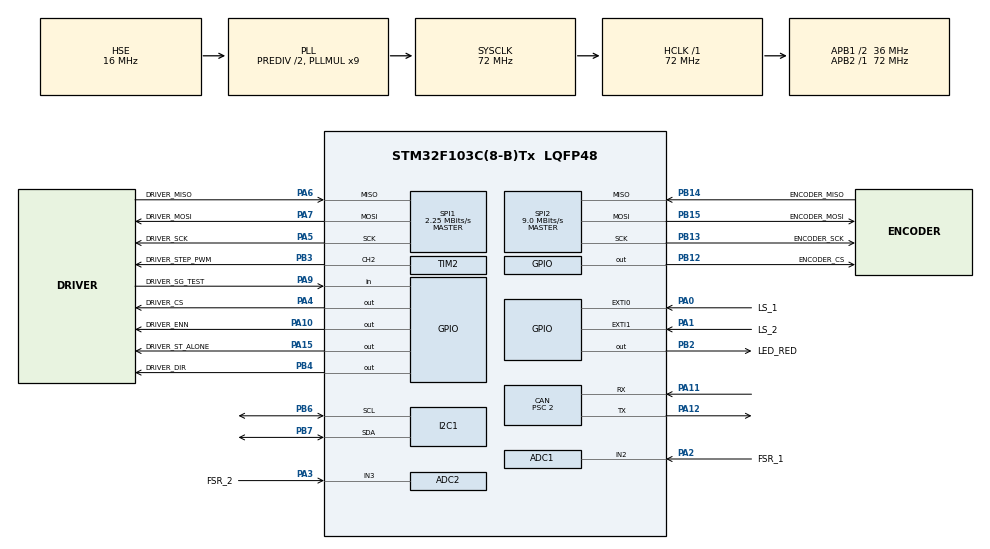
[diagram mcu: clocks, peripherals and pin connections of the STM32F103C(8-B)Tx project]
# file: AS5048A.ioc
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ADC1.Channel-0\#ChannelRegularConversion=ADC_CHANNEL_2
ADC1.EnableAnalogWatchDog=true
ADC1.NbrOfConversionFlag=1
ADC1.Rank-0\#ChannelRegularConversion=1
ADC1.SamplingTime-0\#ChannelRegularConversion=ADC_SAMPLETIME_1CYCLE_5
ADC1.WatchdogChannel=ADC_CHANNEL_2
ADC1.master=1
ADC2.Channel-0\#ChannelRegularConversion=ADC_CHANNEL_3
ADC2.EnableAnalogWatchDog=true
ADC2.NbrOfConversionFlag=1
ADC2.Rank-0\#ChannelRegularConversion=1
ADC2.SamplingTime-0\#ChannelRegularConversion=ADC_SAMPLETIME_1CYCLE_5
ADC2.WatchdogChannel=ADC_CHANNEL_3
CAN.BS1=CAN_BS1_15TQ
CAN.BS2=CAN_BS2_2TQ
CAN.CalculateBaudRate=1000000
CAN.CalculateTimeBit=1000
CAN.CalculateTimeQuantum=55.55555555555556
CAN.NART=ENABLE
CAN.Prescaler=2
CAN.SJW=CAN_SJW_2TQ
Mcu.Family=STM32F1
Mcu.Name=STM32F103C(8-B)Tx
Mcu.Package=LQFP48
NVIC.ADC1_2_IRQn=true\:0\:0\:false\:false\:true\:true\:true\:true
NVIC.EXTI0_IRQn=true\:1\:0\:true\:false\:true\:true\:true\:true
NVIC.EXTI1_IRQn=true\:1\:0\:true\:false\:true\:true\:true\:true
NVIC.PriorityGroup=NVIC_PRIORITYGROUP_4
NVIC.USB_LP_CAN1_RX0_IRQn=true\:2\:0\:true\:false\:true\:true\:true\:true
PA0-WKUP.GPIO_Label=LS_1
PA0-WKUP.GPIO_ModeDefaultEXTI=GPIO_MODE_IT_RISING_FALLING
PA0-WKUP.Signal=GPXTI0
PA1.GPIO_Label=LS_2
PA1.GPIO_ModeDefaultEXTI=GPIO_MODE_IT_RISING_FALLING
PA1.Signal=GPXTI1
PA10.GPIO_Label=DRIVER_ENN
PA10.Signal=GPIO_Output
PA11.Mode=CAN_Activate
PA11.Signal=CAN_RX
PA12.Mode=CAN_Activate
PA12.Signal=CAN_TX
PA13.Mode=Serial_Wire
PA13.Signal=SYS_JTMS-SWDIO
PA14.Mode=Serial_Wire
PA14.Signal=SYS_JTCK-SWCLK
PA15.GPIO_Label=DRIVER_ST_ALONE
PA15.Signal=GPIO_Output
PA2.GPIO_Label=FSR_1
PA2.Signal=ADCx_IN2
PA3.GPIO_Label=FSR_2
PA3.Signal=ADCx_IN3
PA4.GPIO_Label=DRIVER_CS
PA4.Signal=GPIO_Output
PA5.GPIO_Label=DRIVER_SCK
PA5.Mode=Full_Duplex_Master
PA5.Signal=SPI1_SCK
PA6.GPIO_Label=DRIVER_MISO
PA6.Mode=Full_Duplex_Master
PA6.Signal=SPI1_MISO
PA7.GPIO_Label=DRIVER_MOSI
PA7.Mode=Full_Duplex_Master
PA7.Signal=SPI1_MOSI
PA9.GPIO_Label=DRIVER_SG_TEST
PA9.Signal=GPIO_Input
PB12.GPIO_Label=ENCODER_CS
PB12.Signal=GPIO_Output
PB13.GPIO_Label=ENCODER_SCK
PB13.Mode=Full_Duplex_Master
PB13.Signal=SPI2_SCK
PB14.GPIO_Label=ENCODER_MISO
PB14.Mode=Full_Duplex_Master
PB14.Signal=SPI2_MISO
PB15.GPIO_Label=ENCODER_MOSI
PB15.Mode=Full_Duplex_Master
PB15.Signal=SPI2_MOSI
PB2.GPIO_Label=LED_RED
PB2.Signal=GPIO_Output
PB3.GPIO_Label=DRIVER_STEP_PWM
PB3.Signal=S_TIM2_CH2
PB4.GPIO_Label=DRIVER_DIR
PB4.Signal=GPIO_Output
PB6.Mode=I2C
PB6.Signal=I2C1_SCL
PB7.Mode=I2C
PB7.Signal=I2C1_SDA
PD0-OSC_IN.Mode=HSE-External-Oscillator
PD0-OSC_IN.Signal=RCC_OSC_IN
PD1-OSC_OUT.Mode=HSE-External-Oscillator
PD1-OSC_OUT.Signal=RCC_OSC_OUT
ProjectManager.HeapSize=0x200
ProjectManager.StackSize=0x400
ProjectManager.TargetToolchain=STM32CubeIDE
RCC.ADCPresc=RCC_ADCPCLK2_DIV6
RCC.AHBFreq_Value=72000000
RCC.APB1CLKDivider=RCC_HCLK_DIV2
RCC.APB1Freq_Value=36000000
RCC.APB1TimFreq_Value=72000000
RCC.APB2Freq_Value=72000000
RCC.APB2TimFreq_Value=72000000
RCC.HCLKFreq_Value=72000000
RCC.HSEDivPLL=RCC_HSE_PREDIV_DIV2
RCC.HSE_VALUE=16000000
RCC.PLLMUL=RCC_PLL_MUL9
RCC.PLLSourceVirtual=RCC_PLLSOURCE_HSE
RCC.SYSCLKFreq_VALUE=72000000
RCC.SYSCLKSource=RCC_SYSCLKSOURCE_PLLCLK
RCC.USBFreq_Value=72000000
SH.ADCx_IN2.0=ADC1_IN2,IN2
SH.ADCx_IN3.0=ADC2_IN3,IN3
SH.S_TIM2_CH2.0=TIM2_CH2,PWM Generation2 CH2
SPI1.BaudRatePrescaler=SPI_BAUDRATEPRESCALER_32
SPI1.CalculateBaudRate=2.25 MBits/s
SPI1.Direction=SPI_DIRECTION_2LINES
SPI1.Mode=SPI_MODE_MASTER
SPI1.VirtualType=VM_MASTER
SPI2.BaudRatePrescaler=SPI_BAUDRATEPRESCALER_4
SPI2.CLKPhase=SPI_PHASE_2EDGE
SPI2.CalculateBaudRate=9.0 MBits/s
SPI2.Direction=SPI_DIRECTION_2LINES
SPI2.Mode=SPI_MODE_MASTER
SPI2.VirtualType=VM_MASTER
TIM2.Channel-PWM\ Generation2\ CH2=TIM_CHANNEL_2
TIM2.Period=65535
board=custom

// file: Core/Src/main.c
/* USER CODE BEGIN Header */
/**
  ******************************************************************************
  * @file           : main.c
  * @brief          : Main program body
  ******************************************************************************
  * @attention
  *
  * Copyright (c) 2024 STMicroelectronics.
  * All rights reserved.
  *
  * This software is licensed under terms that can be found in the LICENSE file
  * in the root directory of this software component.
  * If no LICENSE file comes with this software, it is provided AS-IS.
  *
  ******************************************************************************
  */
/* USER CODE END Header */
#include "main.h"
#include "adc.h"
#include "can.h"
#include "i2c.h"
#include "spi.h"
#include "tim.h"
#include "gpio.h"

/* USER CODE BEGIN Includes */
#include "as5048a.h"

/* USER CODE END Includes */

void SystemClock_Config(void);

int main(void)
{

  /* MCU Configuration--------------------------------------------------------*/

  /* Reset of all peripherals, Initializes the Flash interface and the Systick. */
  HAL_Init();

  /* Configure the system clock */
  SystemClock_Config();

  /* Initialize all configured peripherals */
  MX_GPIO_Init();
  MX_CAN_Init();
  MX_I2C1_Init();
  MX_SPI1_Init();
  MX_SPI2_Init();
  MX_ADC1_Init();
  MX_ADC2_Init();
  MX_TIM2_Init();
  /* USER CODE BEGIN 2 */
  MX_AS5048A_1_Init();
  /* USER CODE END 2 */

  /* Infinite loop */
  /* USER CODE BEGIN WHILE */
  while (1)
  {
      AS5048A_ReadAngle(&as5048a_1);
    /* USER CODE END WHILE */

  }
}

void SystemClock_Config(void)
{
  RCC_OscInitTypeDef RCC_OscInitStruct = {0};
  RCC_ClkInitTypeDef RCC_ClkInitStruct = {0};
  RCC_PeriphCLKInitTypeDef PeriphClkInit = {0};

  /** Initializes the RCC Oscillators according to the specified parameters
  * in the RCC_OscInitTypeDef structure.
  */
  RCC_OscInitStruct.OscillatorType = RCC_OSCILLATORTYPE_HSE;
  RCC_OscInitStruct.HSEState = RCC_HSE_ON;
  RCC_OscInitStruct.HSEPredivValue = RCC_HSE_PREDIV_DIV2;
  RCC_OscInitStruct.HSIState = RCC_HSI_ON;
  RCC_OscInitStruct.PLL.PLLState = RCC_PLL_ON;
  RCC_OscInitStruct.PLL.PLLSource = RCC_PLLSOURCE_HSE;
  RCC_OscInitStruct.PLL.PLLMUL = RCC_PLL_MUL9;
  if (HAL_RCC_OscConfig(&RCC_OscInitStruct) != HAL_OK)
  {
    Error_Handler();
  }

  /** Initializes the CPU, AHB and APB buses clocks
  */
  RCC_ClkInitStruct.ClockType = RCC_CLOCKTYPE_HCLK|RCC_CLOCKTYPE_SYSCLK
                              |RCC_CLOCKTYPE_PCLK1|RCC_CLOCKTYPE_PCLK2;
  RCC_ClkInitStruct.SYSCLKSource = RCC_SYSCLKSOURCE_PLLCLK;
  RCC_ClkInitStruct.AHBCLKDivider = RCC_SYSCLK_DIV1;
  RCC_ClkInitStruct.APB1CLKDivider = RCC_HCLK_DIV2;
  RCC_ClkInitStruct.APB2CLKDivider = RCC_HCLK_DIV1;

  if (HAL_RCC_ClockConfig(&RCC_ClkInitStruct, FLASH_LATENCY_2) != HAL_OK)
  {
    Error_Handler();
  }
  PeriphClkInit.PeriphClockSelection = RCC_PERIPHCLK_ADC;
  PeriphClkInit.AdcClockSelection = RCC_ADCPCLK2_DIV6;
  if (HAL_RCCEx_PeriphCLKConfig(&PeriphClkInit) != HAL_OK)
  {
    Error_Handler();
  }
}

void Error_Handler(void)
{
  __disable_irq();
  while (1)
  {
  }
}
